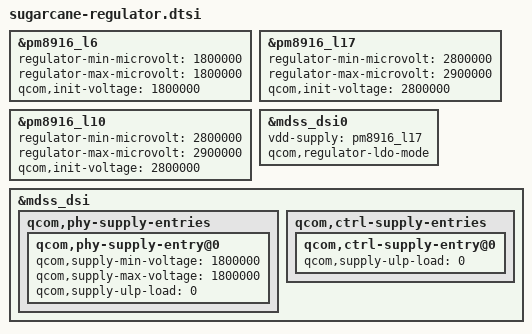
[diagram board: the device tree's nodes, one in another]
&pm8916_l6 {
	regulator-min-microvolt = <1800000>;
	regulator-max-microvolt = <1800000>;
	qcom,init-voltage = <1800000>;
};

&pm8916_l17 {
	regulator-min-microvolt = <2800000>;
	regulator-max-microvolt = <2900000>;
	qcom,init-voltage = <2800000>;
};

&pm8916_l10 {
	regulator-min-microvolt = <2800000>;
	regulator-max-microvolt = <2900000>;
	qcom,init-voltage = <2800000>;
};

&mdss_dsi0 {
	vdd-supply = <&pm8916_l17>;
	qcom,regulator-ldo-mode;
};

&mdss_dsi {	
	qcom,phy-supply-entries {
		qcom,phy-supply-entry@0 {
			qcom,supply-min-voltage = <1800000>;
			qcom,supply-max-voltage = <1800000>;
			qcom,supply-ulp-load = <0>;
		};
	};

	qcom,ctrl-supply-entries {
		qcom,ctrl-supply-entry@0 {
			qcom,supply-ulp-load = <0>;
		};
	};
};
